# RL6955_IP_SVD register map
Vendor: Realtek
Registers are 32-bit, read-write, reset 0x0 unless marked. A register's access mark holds for its fields unless they carry their own. Offsets are from the block's base; [hi:lo] are bit positions; {n}, {i} and the like mark numbered series.

## PAGE4
Base 0x40000000
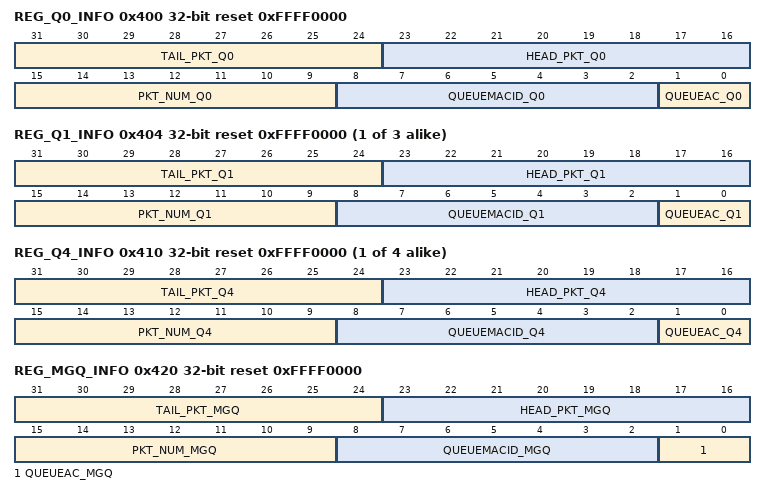
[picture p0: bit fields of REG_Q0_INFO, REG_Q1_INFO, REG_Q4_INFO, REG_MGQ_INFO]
0x400 REG_Q0_INFO ro reset 0xFFFF0000
  [31:24] TAIL_PKT_Q0 — The LLT index of the last packet of QUEUE0.
  [23:16] HEAD_PKT_Q0 — The LLT index of the first packet of QUEUE0.
  [15:9] PKT_NUM_Q0 — The total QUEUE0 pkt number in TxLLT
  [8:2] QUEUEMACID_Q0 — MacID of head pkt
  [1:0] QUEUEAC_Q0 — AC type of QUEUE0
{0x400+4i} REG_Q{i}_INFO ro reset 0xFFFF0000 (i=1..3)
  [31:24] TAIL_PKT_Q{i} — The LLT index of the last packet of QUEUE{i}.
  [23:16] HEAD_PKT_Q{i} — The LLT index of the first packet of QUEUE{i}.
  [15:9] PKT_NUM_Q{i} — The total QUEUE1 pkt number in TxLLT
  [8:2] QUEUEMACID_Q{i} — MacID of head pkt
  [1:0] QUEUEAC_Q{i} — AC type of QUEUE{i}
{0x400+4i} REG_Q{i}_INFO ro reset 0xFFFF0000 (i=4..7)
  [31:24] TAIL_PKT_Q{i} — The LLT index of the last packet of QUEUE{i}.
  [23:16] HEAD_PKT_Q{i} — The LLT index of the first packet of QUEUE{i}.
  [15:9] PKT_NUM_Q{i} — The total QUEUE{i} pkt number in TxLLT
  [8:2] QUEUEMACID_Q{i} — MacID of head pkt
  [1:0] QUEUEAC_Q{i} — AC type of QUEUE{i}
0x420 REG_MGQ_INFO ro reset 0xFFFF0000
  [31:24] TAIL_PKT_MGQ — The LLT index of the last packet of MGQ.
  [23:16] HEAD_PKT_MGQ — The LLT index of the first packet of MGQ.
  [15:9] PKT_NUM_MGQ — The total MGQ pkt number in TxLLT
  [8:2] QUEUEMACID_MGQ — MacID of head pkt
  [1:0] QUEUEAC_MGQ — AC type of MGQ
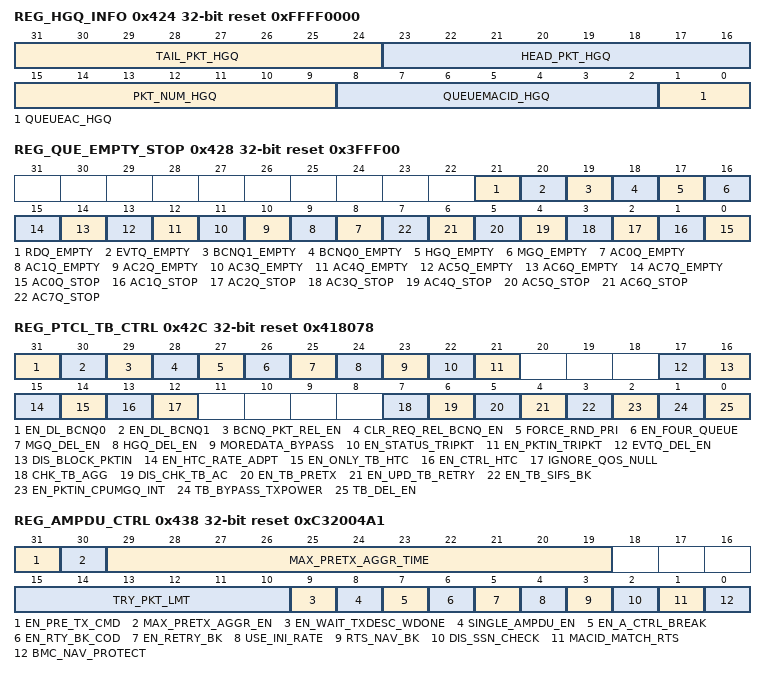
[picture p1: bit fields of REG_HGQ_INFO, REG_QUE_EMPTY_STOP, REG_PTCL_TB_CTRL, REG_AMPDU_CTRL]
0x424 REG_HGQ_INFO ro reset 0xFFFF0000
  [31:24] TAIL_PKT_HGQ — The LLT index of the last packet of HGQ.
  [23:16] HEAD_PKT_HGQ — The LLT index of the first packet of HGQ.
  [15:9] PKT_NUM_HGQ — The total HGQ pkt number in TxLLT
  [8:2] QUEUEMACID_HGQ — MacID of head pkt
  [1:0] QUEUEAC_HGQ — AC type of HGQ
0x428 REG_QUE_EMPTY_STOP ro reset 0x3FFF00
  [21] RDQ_EMPTY — When this bit is raised, RDQ queue is empty. Report by MAC.
  [20] EVTQ_EMPTY — When this bit is raised, EVTQ queue is empty. Report by MAC.
  [19] BCNQ1_EMPTY — When this bit is raised, beacon queue of PORT2 sync beacon / PORT2 disc beacon empty.
  [18] BCNQ0_EMPTY — When this bit is raised, beacon queue of PORT1 SoftAP beacon is empty.
  [17] HGQ_EMPTY — When this bit is raised, HGQ queue is empty. Report by MAC.
  [16] MGQ_EMPTY — When this bit is raised, MGQ queue is empty. Report by MAC.
  [n+8] AC{n}Q_EMPTY (n=0..7) — When this bit is raised, AC{n} queue is empty. Report by MAC.
  [n] AC{n}Q_STOP (n=0..7) — When this bit is raised, AC{n} queue is stop. Report by MAC.
0x42C REG_PTCL_TB_CTRL reset 0x418078
  [31] EN_DL_BCNQ0 — 1: ptcl consider there is bcn pkt in TXBUF when bcn pkt first be transferd in; 0: mask bcn pkt num in bcn queue
  [30] EN_DL_BCNQ1 — 1: ptcl consider there is bcn pkt in TXBUF when bcn pkt first be transferd in; 0: mask bcn pkt num in bcn queue
  [29] BCNQ_PKT_REL_EN — If this bit is set, the BCN pkt will be set to non-valid after BCN TX.
  [28] CLR_REQ_REL_BCNQ_EN — If this bit is set, the BCN pkt will be set to non-valid when scheduler clear TX BCN CMD even non-TX.
  [27] FORCE_RND_PRI — queue select priority control 1:old round robin method 0:depend on last selected queue
  [26] EN_FOUR_QUEUE — 1: Enable 88C 4AC Mode 0: Enable 8723 ACQ0~7 Mode
  [25] MGQ_DEL_EN — 1: MGQ packet will be dropped when enable macid delete function; 0: MGQ packet cannot be dropped
  [24] HGQ_DEL_EN — 1: HGQ packet will be dropped when enable macid delete function; 0: HGQ packet cannot be dropped
  [23] MOREDATA_BYPASS — For HGQ moredata field. 1: bypass txdesc.moredata bit
  [22] EN_STATUS_TRIPKT
  [21] EN_PKTIN_TRIPKT — If trigger frame is transmitted into txpktbuf, HW generates interrupt 1: Enable 0: Disable
  [17] EVTQ_DEL_EN — 1: EVTQ packet will be dropped when enable macid delete function; 0: EVTQ packet cannot be dropped
  [16] DIS_BLOCK_PKTIN — 1: allow different macid+ac packet assigned to same ACQ queue
  [15] EN_HTC_RATE_ADPT — 1: if tx data rate fallback to CCK/OFDM rate, HW will remove HTC field in mac header
  [14] EN_ONLY_TB_HTC — 1: only TB can carry HTC field
  [13] EN_CTRL_HTC — 1: rts/cts2s/cts2ap/bar will carry HTC field by ctrl_wrapper frame, valid when txdesc.HTC = 1 0: rts/cts2s/cts2ap/bar will NOT carry HTC field even though txdesc.HTC = 1
  [12] IGNORE_QOS_NULL — 1: will not TX QoS Null when rx Basic trigger
  [7] CHK_TB_AGG — When this bit is set, check agg_max_num and agg_max_time
  [6] DIS_CHK_TB_AC — When this bit is set, don't care the AC of DATA
  [5] EN_TB_PRETX — When this bit is set, enable pretx function of TB PPDU, assert txen before gen_cmd_rdy.
  [4] EN_UPD_TB_RETRY — enable write retrybit in MH and add retrycnt when TB PPDU TX fail.
  [3] EN_TB_SIFS_BK — If sifs_timeout_tb_ref (from trxptcl) asserted, break the aggr process of TB PPDU
  [2] EN_PKTIN_CPUMGQ_INT — If cpumgq pktin, HW generates pktin interrupt 1: Enable 0: Disable
  [1] TB_BYPASS_TXPOWER — 1: NOT abort TB PPDU even the txpwr_abort_tx_idx(from txpwr_ctrl) is illegal 0: enable tx power abort TB
  [0] TB_DEL_EN — Enable TB PPDU packet delete: 1) pkt_ageout; 2) macid_delete
0x430 REG_BCNQ_ADDR0
  [31:0] BCNQ_ADDR0 — The address of beacon frame in host memory. For SoftAP beacon(P1) Generate a pulse to inform the update of ADDR
0x434 REG_BCNQ_ADDR1
  [31:0] BCNQ_ADDR1 — The address of beacon frame in host memory. For NAN sync Beacon (P2, 2.4G and 5G) and NAN Disc Beacon (P2) Generate a pulse to inform the update of ADDR
0x438 REG_AMPDU_CTRL reset 0xC32004A1
  [31] EN_PRE_TX_CMD — enable pre tx cmd to use aggr more packet
  [30] MAX_PRETX_AGGR_EN — 1: enable PRETX function, default is enable 0: disable PRETX function
  [29:19] MAX_PRETX_AGGR_TIME — If BIT_PRETX_AGGR_EN = 1, the bits will count down after PHYTXON signal asserting every transmission in pre-tx mode.(Default: 23F, mac_clk = 20MHz, 3us;Smart,mac_clk = 40MHz, 3.5us)
  [15:10] TRY_PKT_LMT — aggr packet limit valid when Try_rate of txdesc or ctrl_info is 1
  [9] EN_WAIT_TXDESC_WDONE — 1: wait write txdesc done before assert set_cmd_p
  [8] SINGLE_AMPDU_EN — If this bit is set, Enable single sub-frame APMDU.
  [7] EN_A_CTRL_BREAK — 1: break the AGGR process when the a_ctrl field in TXDESC is different
  [6] EN_RTY_BK_COD — AMPDU aggregation mode with retry MPDUs and new MPDUs. When this bit is enabled, if new MPDU's data rate is not the same as retry MPDUs' fallback data rate, the aggregation will be broken.
  [5] EN_RETRY_BK — AMPDU aggregation mode with retry MPDUs and new MPDUs. When this bit is clear enabled, an AMPDU aggregates retried MPDU and new MPDU. All the aggregation criteria is still the same with normal AMPDU operation.
  [4] USE_INI_RATE — 0: If Txdesc's USE RATE = 0 and this field is equal to 0, the datarate of TXRPT SRAM is used as tx pkt's datarate. (ECO flow) 1: TXInfo's datarate is used as tx pkt's datarate.
  [3] RTS_NAV_BK — Control The RTS NAV criteria for TX. When this bit is clear, TX may aggregates only according to the number of MPDUs existing in the TXPKTBUF, the limit of aggregation size and number, and also the break time. When this bit is set, TX will be under the RTS NAV criteria. No excess RTS NAV is allowed.
  [2] DIS_SSN_CHECK — Disable checker the SSN rule when generating AMPDU TX cmd.
  [1] MACID_MATCH_RTS — Enable the packet that follow the RTS have same MACID
  [0] BMC_NAV_PROTECT — Enable the NAV protection when transmit broadcast/multicast
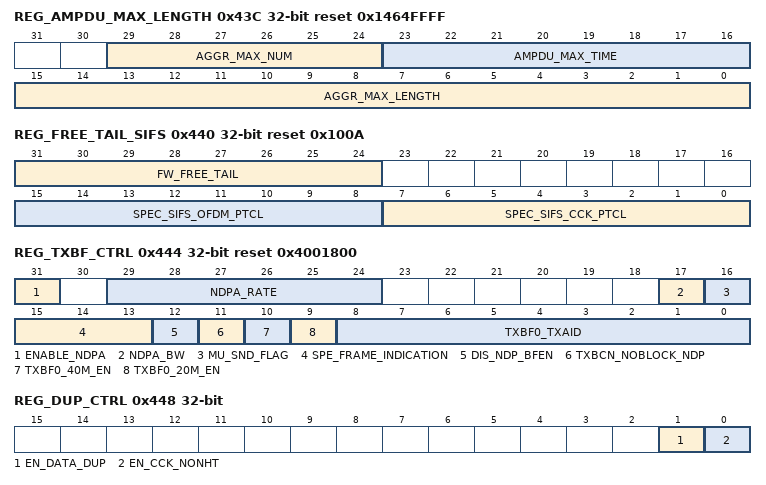
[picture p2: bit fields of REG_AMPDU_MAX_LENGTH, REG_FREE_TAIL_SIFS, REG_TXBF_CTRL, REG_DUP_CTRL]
0x43C REG_AMPDU_MAX_LENGTH reset 0x1464FFFF
  [29:24] AGGR_MAX_NUM — the maximum aggregation packet number limit
  [23:16] AMPDU_MAX_TIME — AMPDU duration limit in the unit of 32us.
  [15:0] AGGR_MAX_LENGTH — AMPDU length limit, unit:128Byte
0x440 REG_FREE_TAIL_SIFS access per field reset 0x100A
  [31:24] FW_FREE_TAIL ro — Real-time Free Tail LLT_index Number
  [15:8] SPEC_SIFS_OFDM_PTCL rw — The spec SIFS value for duration calculation
  [7:0] SPEC_SIFS_CCK_PTCL rw — The spec SIFS value for duration calculation
0x444 REG_TXBF_CTRL reset 0x4001800
  [31] ENABLE_NDPA — Set '1' for MAC to enable sending NDPA or NDP Announcement MPDU
  [29:24] NDPA_RATE — NDPA tx rate setting, from CCK 1M to HE NSS1 MCS9
  [17] NDPA_BW — NDPA bandwidth setting 1: 40M 0: 20M
  [16] MU_SND_FLAG — indicate the MU Beamforming, used for verification. Assert when the packet is MU-NDPA or BFRP
  [15:13] SPE_FRAME_INDICATION — indicate some specific frame, used for verification. Co-work with TXDESC.RAW and MU_SND_FLAG. 000: not specified 001: BFRP (VHT MU BF) 100: TF MU-RTS 101: TF-BFRP (HE MU BF) 111: OTHER Trigger Frame
  [12] DIS_NDP_BFEN — 1: disable beamforming with NDP
  [11] TXBCN_NOBLOCK_NDP — beacon packet will not block NDP packet
  [10] TXBF0_40M_EN — TxBF status of beamformee0 @BW=40M
  [9] TXBF0_20M_EN — TxBF status of beamformee0 @BW=20M
  [8:0] TXBF0_TXAID — P_AID[8:0] of the associated beamformee0
0x448 REG_DUP_CTRL
  [1] EN_DATA_DUP — 1: enable data duplicate @ CCK/OFDM rate
  [0] EN_CCK_NONHT — 1: enable signaling TA or duplicate of CCK rate
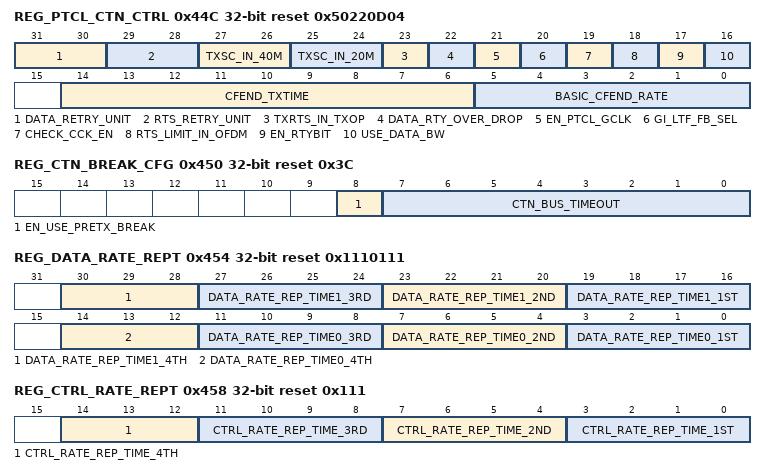
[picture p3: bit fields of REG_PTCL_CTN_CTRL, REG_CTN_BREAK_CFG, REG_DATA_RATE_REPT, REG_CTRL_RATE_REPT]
0x44C REG_PTCL_CTN_CTRL reset 0x50220D04
  [31:30] DATA_RETRY_UNIT — indicate the unit of ctrl_info/txdesc data_retry_limit 0: unit=1 1: unit=2
  [29:28] RTS_RETRY_UNIT — indicate the unit of ctrl_info/txdesc rts_retry_limit 0: unit=1 1: unit=2 2: unit=4
  [27:26] TXSC_IN_40M — Value of Data frame Tx sub-carrier mode 40MHz
  [25:24] TXSC_IN_20M — Value of Data frame Tx sub-carrier mode 20MHz
  [23] TXRTS_IN_TXOP — 1: can tx rts in txop
  [22] DATA_RTY_OVER_DROP — 1: only drop when data retry over 0: drop when data or rts retry over
  [21] EN_PTCL_GCLK — 1: enable clock gating
  [20] GI_LTF_FB_SEL — 0: no GI_LTF fallback 1: GI_LTF fallback option 1 enabled (downgrade GI_LTF first from init. rate)
  [19] CHECK_CCK_EN — If this bit is set, HW check Tx pkt's data rate. When data rate is CCK rate, modify the rate to NON_CCK_RATE.
  [18] RTS_LIMIT_IN_OFDM — Rts rate will not down to cck rate
  [17] EN_RTYBIT — 1: update Retry Bit in mac header 0: Disable
  [16] USE_DATA_BW — 1 : Use des2_data_bw for this packet 0 : when des1_cca_rts = 2'b10, update_bw depend on ch_bw_status
  [14:6] CFEND_TXTIME — Cfend packet txtime bit[8:0]
  [5:0] BASIC_CFEND_RATE — The initial rate for basic CFEND frame transmitted as EDCA originator. The response control frame shall be selected by the definition of 802.11n. OFDM6M
0x450 REG_CTN_BREAK_CFG reset 0x3C
  [8] EN_USE_PRETX_BREAK — 1: use max_pretx_aggr_break to replace sifs_break when en_pretx_cmd, for longer gen_cmd time
  [7:0] CTN_BUS_TIMEOUT — when sifs_bk or max_pretx_aggr_break occurs during FETCH_TXDESC, wait bus respond, timeout will break early unit: 1T mac_clk, default 16T
0x454 REG_DATA_RATE_REPT reset 0x1110111
  [30:28] DATA_RATE_REP_TIME1_4TH — DATA1 indicate the number of repetitions of the rate after 3rd rate fallback 0: repeat 1 time 1: repeat 2 times 2: repeat 4 times 3: repeat 8 times 4: repeat 16 times
  [27:24] DATA_RATE_REP_TIME1_3RD — DATA1. selected by ctrl_info The number of repetitions of the third rate
  [23:20] DATA_RATE_REP_TIME1_2ND — DATA1. selected by ctrl_info The number of repetitions of the second rate
  [19:16] DATA_RATE_REP_TIME1_1ST — DATA1. selected by ctrl_info The number of repetitions of the first rate
  [14:12] DATA_RATE_REP_TIME0_4TH — DATA0 indicate the number of repetitions of the rate after 3rd rate fallback 0: repeat 1 time 1: repeat 2 times 2: repeat 4 times 3: repeat 8 times 4: repeat 16 times
  [11:8] DATA_RATE_REP_TIME0_3RD — DATA0 The number of repetitions of the third rate
  [7:4] DATA_RATE_REP_TIME0_2ND — DATA0 The number of repetitions of the second rate
  [3:0] DATA_RATE_REP_TIME0_1ST — DATA0 The number of repetitions of the first rate
0x458 REG_CTRL_RATE_REPT reset 0x111
  [14:12] CTRL_RATE_REP_TIME_4TH — RTA_CTS2S indicate the number of repetitions of the rate after 3rd rate fallback 0: repeat 1 time 1: repeat 2 times 2: repeat 4 times 3: repeat 8 times 4: repeat 16 times
  [11:8] CTRL_RATE_REP_TIME_3RD — RTS/CTS2S The number of repetitions of the third rate
  [7:4] CTRL_RATE_REP_TIME_2ND — RTS/CTS2S The number of repetitions of the second rate
  [3:0] CTRL_RATE_REP_TIME_1ST — RTS/CTS2S The number of repetitions of the first rate
{0x45C+4i} REG_DATA_RATE_MASK{i} (i=0..3)
  [21:0] DATA_RATE_MASK_TABLE_{i} — Data Auto Rate Fallback Table Register {i}, indexed by fb_mask_idx in TXDESC. Each bit is mapped as the following: Bit[0:3] = {1M, 2M, 5.5M, 11M } Bit[4:11] = {6M, 9M, 12M, 18M, 24M, 36M, 48M, 54M} Bit[12:21] = HT/VHT/HE MCS0~MCS9
0x46C REG_CTRL_RATE_MASK
  [21:0] CTRL_RATE_MASK_TABLE — CTRL(RTS/CTS2S) Auto Rate Fallback Table Register. Each bit is mapped as the following: Bit[0:3] = {1M, 2M, 5.5M, 11M } Bit[4:11] = {6M, 9M, 12M, 18M, 24M, 36M, 48M, 54M} Bit[12:21] = HT/VHT/HE MCS0~MCS9
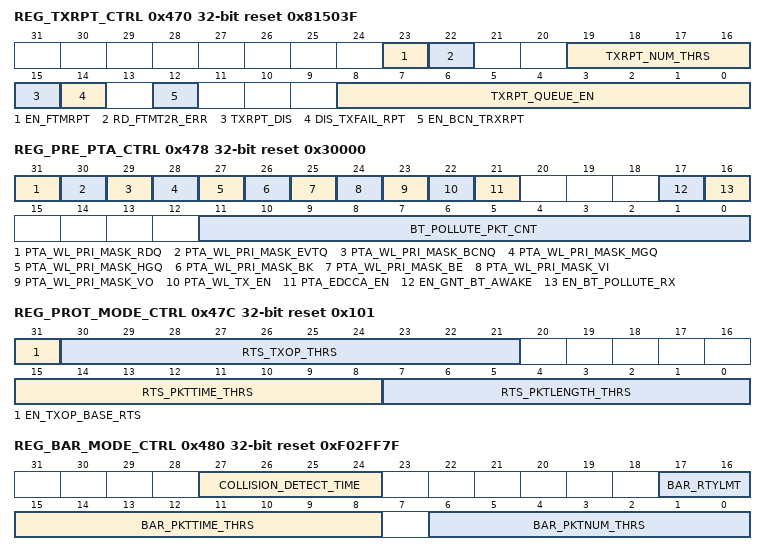
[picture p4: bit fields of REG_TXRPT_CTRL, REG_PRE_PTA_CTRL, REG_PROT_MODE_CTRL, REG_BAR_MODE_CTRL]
0x470 REG_TXRPT_CTRL access per field reset 0x81503F
  [23] EN_FTMRPT rw — When this bit asserted, HW will report FTM rpt
  [22] RD_FTMT2R_ERR ro — Indicates the timeout error in FTM t2r report
  [19:16] TXRPT_NUM_THRS rw — if the number of txrpt exceeds the threshold,then assert txrpt interrupts
  [15] TXRPT_DIS rw — when this bit is enabled, HW will not generate txrpt for driver's fixed rate packets
  [14] DIS_TXFAIL_RPT rw — when this bit is enabled, HW will not generate txrpt for tx failed packets
  [12] EN_BCN_TRXRPT rw — when this bit is enabled, HW will generate txrpt for BCN
  [8:0] TXRPT_QUEUE_EN rw — 1: HW will report tx_status 0: no report BIT0: BK Queue BIT1: BE Queue BIT2: VI Queue BIT3: VO Queue BIT4: MGT Queue BIT5: HG Queue BIT6: BCN Queue BIT7: TB Queue BIT8: EVENT QUEUE
0x478 REG_PRE_PTA_CTRL access per field reset 0x30000
  [31] PTA_WL_PRI_MASK_RDQ rw — PTCL send wl_pri to PTA when pktbuf has RDQ packet
  [30] PTA_WL_PRI_MASK_EVTQ rw — PTCL send wl_pri to PTA when pktbuf has EVTQ packet
  [29] PTA_WL_PRI_MASK_BCNQ rw — PTCL send wl_pri to PTA when pktbuf has BCNQ packet
  [28] PTA_WL_PRI_MASK_MGQ rw — PTCL send wl_pri to PTA when pktbuf has MGQ packet
  [27] PTA_WL_PRI_MASK_HGQ rw — PTCL send wl_pri to PTA when pktbuf has HGQ packet
  [26] PTA_WL_PRI_MASK_BK rw — PTCL send wl_pri to PTA when pktbuf has BKQ packet
  [25] PTA_WL_PRI_MASK_BE rw — PTCL send wl_pri to PTA when pktbuf has BEQ packet
  [24] PTA_WL_PRI_MASK_VI rw — PTCL send wl_pri to PTA when pktbuf has VIQ packet
  [23] PTA_WL_PRI_MASK_VO rw — PTCL send wl_pri to PTA when pktbuf has VOQ packet
  [22] PTA_WL_TX_EN rw — enable WL PTA (should be set in init MAC)
  [21] PTA_EDCCA_EN rw — 0 : wl_tx signal to PTA does not consider EDCCA 1 : wl_tx signal to PTA consider EDCCA
  [17] EN_GNT_BT_AWAKE rw — Enable pollute bit function.(C card ECO item, modify hardware circuit and add two options) 0: Disable 1: Enable When (GNT_BT option/LTE_RX option/(GNT_WL==0)) == 1, retry count can't increase if Tx fail. One or more packets will record in polluted bit field of txreport when txreport generates in Tx ok or tx drop.
  [16] EN_BT_POLLUTE_RX rw — enable write BT Polluted field during RX RESP
  [11:0] BT_POLLUTE_PKT_CNT ro — count the tx fail pkt caused by bt pollute, write 0x46C[11] will clear the counter
0x47C REG_PROT_MODE_CTRL reset 0x101
  [31] EN_TXOP_BASE_RTS — enable TXOP duration-based RTS/CTS
  [30:21] RTS_TXOP_THRS — unit:32us, valid when BIT_EN_TXOP_BASE_RTS = 1
  [15:8] RTS_PKTTIME_THRS — RTS packet txtime threshold, unit is 64 us
  [7:0] RTS_PKTLENGTH_THRS — RTS packet Length threshold, unit is 128 bytes
0x480 REG_BAR_MODE_CTRL reset 0xF02FF7F
  [27:24] COLLISION_DETECT_TIME — 0~15: The field indicated collision detect time for broadcast or Beacon packet.(unit: us)
  [17:16] BAR_RTYLMT — BAR retry limit
  [15:8] BAR_PKTTIME_THRS — BAR packet time thrs
  [6:0] BAR_PKTNUM_THRS
0x484 REG_MACID_DROP
  [31:0] MACID_DROP — Macid31~Macid0 Drop (per bit controlled)
0x488 REG_MACID_PAUSE
  [31:0] MACID_PAUSE — Macid31~Macid 0 Packet Sleep. (per bit controlled)
0x48C REG_MACID_RLS
  [31:0] MACID_RELEASE — Macid31~Macid0 Release(per bit controlled)
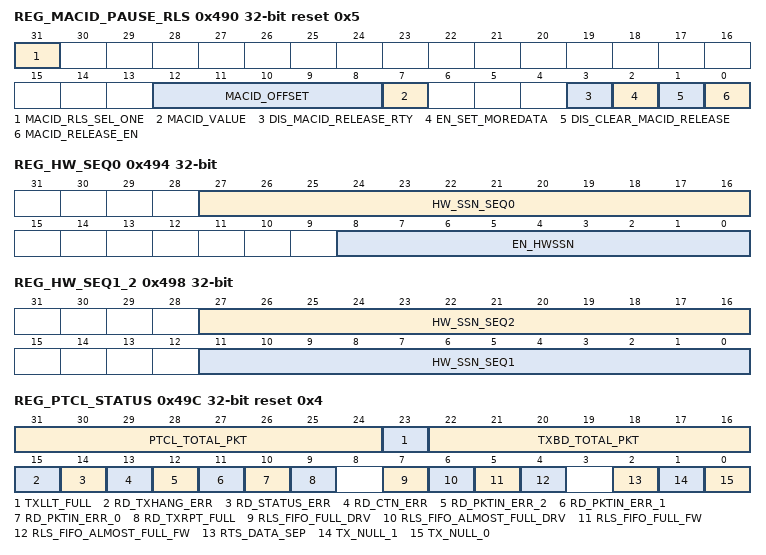
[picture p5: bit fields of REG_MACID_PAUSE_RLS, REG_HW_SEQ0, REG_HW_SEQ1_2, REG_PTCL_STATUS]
0x490 REG_MACID_PAUSE_RLS reset 0x5
  [31] MACID_RLS_SEL_ONE — 1: will TX MPDU during macid_release_mode 0: can TX AMPDU during macid_release_mode
  [12:8] MACID_OFFSET — write this field to set REG_macid_release[macid_offset] = macid_value
  [7] MACID_VALUE — write this field to set REG_macid_release[macid_offset] = macid_value
  [3] DIS_MACID_RELEASE_RTY — when release one packet for a macid, retry should happen on the same ACQ. Set 1 to remove this requirement
  [2] EN_SET_MOREDATA — 1: Enable HW set the more data bit of the PKT that MACID release function tx. 0: Disable HW set the more data bit of the PKT that MACID release function tx.
  [1] DIS_CLEAR_MACID_RELEASE — 1: HW No clear MACID Release bit after release the pkt. 0: HW will clear MACID Release bit after release the pkt.
  [0] MACID_RELEASE_EN — 1: Enable MACID Release function. (same as MACID DROP) 0: Disable MACID Release function.
0x494 REG_HW_SEQ0
  [27:16] HW_SSN_SEQ0 — When TXDESC HWSEQEN is set, MAC will overwrite SEQ control by this register. Before DRV hand over the SEQ control to HW, DRV may set the current SEQ to this register. When DRV will take back the SEQ control from HW, DRV may get the current sequence from this register.
  [8:0] EN_HWSSN — HW update the SSN [6:0], When this bit enable and EN_HWSEQ of TXDESC, MAC will overwrite MACHDR SEQ according to TXDESC QSEL [0] BIT_HWSEQ_VO_EN [1] BIT_HWSEQ_VI_EN [2] BIT_HWSEQ_BE_EN [3] BIT_HWSEQ_BK_EN [4] BIT_HWSEQ_MGT_EN [5] BIT_HWSEQ_HGQ_EN [6] BIT_HWSEQ_BCN_EN,don't care EN_HWSEQ of TXDESC [7] BIT_HWSEQ_TBQ_EN [8] BIT_HWSEQ_EVTQ_EN
0x498 REG_HW_SEQ1_2
  [27:16] HW_SSN_SEQ2 — When TXDESC HWSEQEN is set, MAC will overwrite SEQ control by this register. Before DRV hand over the SEQ control to HW, DRV may set the current SEQ to this register. When DRV will take back the SEQ control from HW, DRV may get the current sequence from this register.
  [11:0] HW_SSN_SEQ1 — When TXDESC HWSEQEN is set, MAC will overwrite SEQ control by this register. Before DRV hand over the SEQ control to HW, DRV may set the current SEQ to this register. When DRV will take back the SEQ control from HW, DRV may get the current sequence from this register.
0x49C REG_PTCL_STATUS access per field reset 0x4
  [31:24] PTCL_TOTAL_PKT ro — Total Packet in LLT
  [23] TXLLT_FULL ro — indicate TXLLT is full
  [22:16] TXBD_TOTAL_PKT ro — Total Packet in TXBD FIFO
  [15] RD_TXHANG_ERR ro — Indicates the txhang error: no tx in 0xFFFF cycle
  [14] RD_STATUS_ERR ro — Indicates the status error: get invalid page (NULL PKT)
  [13] RD_CTN_ERR ro — Indicates the cnt error: get invalid page (NULL PKT)
  [12] RD_PKTIN_ERR_2 ro — Indicates the pktin error: get invalid page (NULL PKT)
  [11] RD_PKTIN_ERR_1 ro — Indicates the pktin error: total page error
  [10] RD_PKTIN_ERR_0 ro — Indicates the pktin error: assign to invalid queue (queue_idx = 0)
  [9] RD_TXRPT_FULL ro — indicates the txrpt buffer is full
  [7] RLS_FIFO_FULL_DRV ro — indicate TXRLS FIFO for driver is full
  [6] RLS_FIFO_ALMOST_FULL_DRV ro — indicate TXRLS FIFO for driver is almost full
  [5] RLS_FIFO_FULL_FW ro — indicate TXRLS FIFO for fw is full
  [4] RLS_FIFO_ALMOST_FULL_FW ro — indicate TXRLS FIFO for fw is almost full
  [2] RTS_DATA_SEP rw — 1:rts retry cnt & retry limit calculate separately
  [1] TX_NULL_1 ro — Port 0/1 Tx Null 1 packet ok indicator
  [0] TX_NULL_0 ro — Port 0/1 Tx Null 0 packet ok indicator
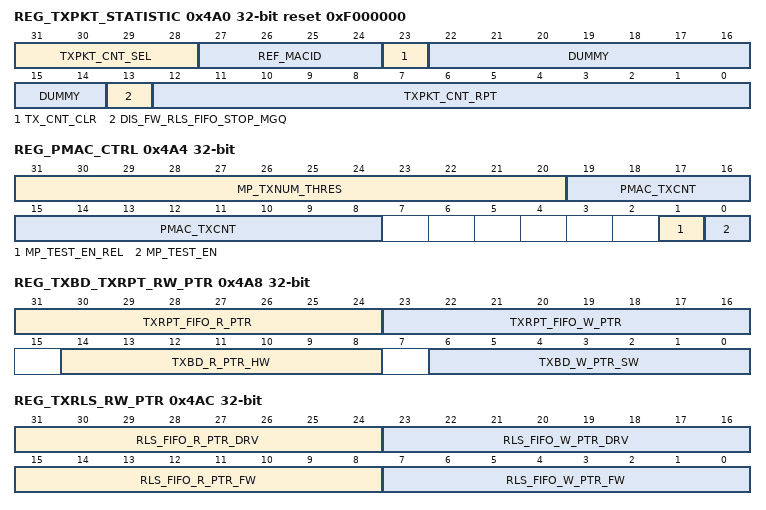
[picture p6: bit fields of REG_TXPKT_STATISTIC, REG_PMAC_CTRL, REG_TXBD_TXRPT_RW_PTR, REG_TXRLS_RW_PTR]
0x4A0 REG_TXPKT_STATISTIC access per field reset 0xF000000
  [31:28] TXPKT_CNT_SEL rw — Select the counter to show in 0X14A0 BIT_TXPKT_CNT_RPT. 0: r_TX_OK_RTY0 1: r_TX_OK_RTY1 2: r_TX_OK_RTY2 3: r_TX_OK_RTY3 4: r_TX_OK_RTY4 5: r_RTY_DROP 6: r_BMC_TXOK 7: r_TOTAL_PKT_CNT
  [27:24] REF_MACID rw — if BIT_REF_MACID = 0xF, count all eligible frames and ignore MACID; else, only count the frames whose MACID = BIT_REF_MACID BMC packet ignore MACID.
  [23] TX_CNT_CLR rw — Write 1 to clear the counters.
  [22:14] DUMMY rw
  [13] DIS_FW_RLS_FIFO_STOP_MGQ rw — 1: don't clear ptcl_mgq_has_pkt when FW release FIFO is full.
  [12:0] TXPKT_CNT_RPT ro — The results of TXPKT counter. Depends on BIT_TXPKT_CNT_SEL.
0x4A4 REG_PMAC_CTRL access per field
  [31:20] MP_TXNUM_THRES rw — threshold for the number of times a frame can be transferred. If the TX counter reaches the BIT_MP_TXNUM_THRES, stop TX
  [19:8] PMAC_TXCNT ro — tx statistic during PMAC
  [1] MP_TEST_EN_REL ro — 1: indicates that it is during the PMAC TX period
  [0] MP_TEST_EN rw — 1: Enable PMAC function, for MP test 0: stop PMAC function
0x4A8 REG_TXBD_TXRPT_RW_PTR ro
  [31:24] TXRPT_FIFO_R_PTR — read pointer of TXRPT FIFO
  [23:16] TXRPT_FIFO_W_PTR — write pointer of TXRPT FIFO
  [14:8] TXBD_R_PTR_HW — read pointer of TXBD FIFO
  [6:0] TXBD_W_PTR_SW — write pointer of TXBD FIFO
0x4AC REG_TXRLS_RW_PTR ro
  [31:24] RLS_FIFO_R_PTR_DRV — read pointer of Driver TXRLS FIFO
  [23:16] RLS_FIFO_W_PTR_DRV — write pointer of Driver TXRLS FIFO
  [15:8] RLS_FIFO_R_PTR_FW — read pointer of FW TXRLS FIFO
  [7:0] RLS_FIFO_W_PTR_FW — write pointer of FW TXRLS FIFO
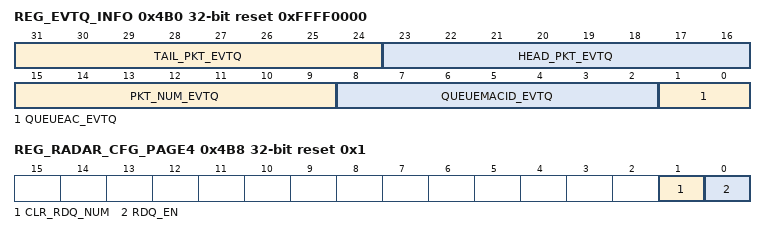
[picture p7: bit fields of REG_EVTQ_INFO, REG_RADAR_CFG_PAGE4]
0x4B0 REG_EVTQ_INFO ro reset 0xFFFF0000
  [31:24] TAIL_PKT_EVTQ — The LLT index of the last packet of EVTQ.
  [23:16] HEAD_PKT_EVTQ — The LLT index of the first packet of EVTQ.
  [15:9] PKT_NUM_EVTQ — The total EVTQ pkt number in TxLLT
  [8:2] QUEUEMACID_EVTQ — MacID of head pkt
  [1:0] QUEUEAC_EVTQ — AC type of EVTQ
0x4B4 REG_RADAR_ADDR
  [31:0] RADAR_ADDR — The address of RADAR frame in host memory. Generate a pulse to inform the update of ADDR
0x4B8 REG_RADAR_CFG_PAGE4 reset 0x1
  [1] CLR_RDQ_NUM — Clear rdq pkt number
  [0] RDQ_EN — 1: en rdq, can pktin
0x4FC REG_DUMMY_PAGE4
  [31:0] DUMMY
